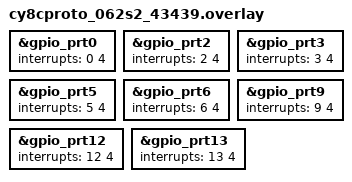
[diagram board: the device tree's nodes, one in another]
/*
 * SPDX-FileCopyrightText: Copyright (c) 2026 Infineon Technologies AG,
 * SPDX-FileCopyrightText: or an affiliate of Infineon Technologies AG. All rights reserved.
 *
 * SPDX-License-Identifier: Apache-2.0
 */

/* Changed default interrupts priority for GPIO to 4 */
&gpio_prt0 {
	interrupts = <0 4>;
};

&gpio_prt2 {
	interrupts = <2 4>;
};

&gpio_prt3 {
	interrupts = <3 4>;
};

&gpio_prt5 {
	interrupts = <5 4>;
};

&gpio_prt6 {
	interrupts = <6 4>;
};

&gpio_prt9 {
	interrupts = <9 4>;
};

&gpio_prt12 {
	interrupts = <12 4>;
};

&gpio_prt13 {
	interrupts = <13 4>;
};
